AUTOSAR XML (schema 4-2-2)
package /Components
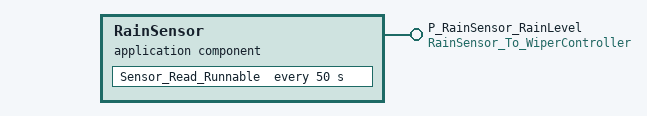
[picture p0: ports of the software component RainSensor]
  application sw component type RainSensor
    provide port P_RainSensor_RainLevel: provided-interface=RainSensor_To_WiperController
    behavior RainSensor_Behavior
      init event SensorInitEvent: start-on-event=Sensor_Read_Runnable
      timing event SensorSampleEvent: start-on-event=Sensor_Read_Runnable, period=50
      runnable Sensor_Read_Runnable: minimum-start-interval=50, symbol=RainSensor_Sensor_Read
        data-send-points:
          access Rain_Level_SendPoint: accessed-variable=P_RainSensor_RainLevel.rain_level
